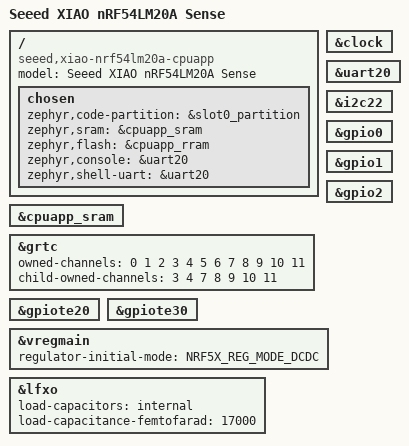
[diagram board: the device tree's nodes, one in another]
/*
 * SPDX-License-Identifier: Apache-2.0
 *
 * Seeed XIAO nRF54LM20A Sense -- application core (secure).
 * See docs/nrf54lm20a-board.md for the full pin/power reference.
 */

/dts-v1/;
#include <nordic/nrf54lm20a_enga_cpuapp.dtsi>
#include "seeed_xiao_nrf54lm20a_connector.dtsi"
#include "xiao_nrf54lm20a_common.dtsi"

/ {
	model = "Seeed XIAO nRF54LM20A Sense";
	compatible = "seeed,xiao-nrf54lm20a-cpuapp";

	chosen {
		zephyr,code-partition = &slot0_partition;
		zephyr,sram = &cpuapp_sram;
		zephyr,flash = &cpuapp_rram;
		zephyr,console = &uart20;
		zephyr,shell-uart = &uart20;
	};
};

&cpuapp_sram {
	status = "okay";
};

&grtc {
	owned-channels = <0 1 2 3 4 5 6 7 8 9 10 11>;
	child-owned-channels = <3 4 7 8 9 10 11>;
	status = "okay";
};

&clock {
	status = "okay";
};

&uart20 {
	status = "okay";
};

&i2c22 {
	status = "okay";
};

&gpio0 {
	status = "okay";
};

&gpio1 {
	status = "okay";
};

&gpio2 {
	status = "okay";
};

&gpiote20 {
	status = "okay";
};

&gpiote30 {
	status = "okay";
};

&vregmain {
	status = "okay";
	regulator-initial-mode = <NRF5X_REG_MODE_DCDC>;
};

&lfxo {
	load-capacitors = "internal";
	load-capacitance-femtofarad = <17000>;
	status = "okay";
};

/* Default memory partition layout for the nRF54LM20A. */
#include <nordic/nrf54lm20a_partition.dtsi>
